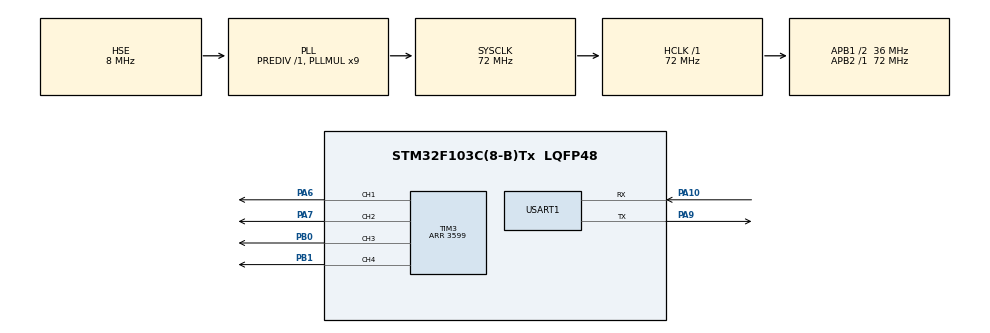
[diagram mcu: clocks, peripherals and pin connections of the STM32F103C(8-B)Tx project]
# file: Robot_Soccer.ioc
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FREERTOS.Tasks01=defaultTask,24,128,StartDefaultTask,Default,NULL,Dynamic,NULL,NULL;UART_Task,32,128,StartUARTTask,Default,NULL,Dynamic,NULL,NULL;Motor_Task,24,128,StartMotorTask,Default,NULL,Dynamic,NULL,NULL
Mcu.Family=STM32F1
Mcu.Name=STM32F103C(8-B)Tx
Mcu.Package=LQFP48
NVIC.PriorityGroup=NVIC_PRIORITYGROUP_4
NVIC.TIM2_IRQn=true\:15\:0\:false\:false\:true\:false\:false\:true\:true
NVIC.TimeBase=TIM2_IRQn
NVIC.TimeBaseIP=TIM2
NVIC.USART1_IRQn=true\:5\:0\:false\:false\:true\:true\:true\:true\:true
PA10.Mode=Asynchronous
PA10.Signal=USART1_RX
PA13.Mode=Serial_Wire
PA13.Signal=SYS_JTMS-SWDIO
PA14.Mode=Serial_Wire
PA14.Signal=SYS_JTCK-SWCLK
PA6.Signal=S_TIM3_CH1
PA7.Signal=S_TIM3_CH2
PA9.Mode=Asynchronous
PA9.Signal=USART1_TX
PB0.Signal=S_TIM3_CH3
PB1.Signal=S_TIM3_CH4
PD0-OSC_IN.Mode=HSE-External-Oscillator
PD0-OSC_IN.Signal=RCC_OSC_IN
PD1-OSC_OUT.Mode=HSE-External-Oscillator
PD1-OSC_OUT.Signal=RCC_OSC_OUT
ProjectManager.HeapSize=0x200
ProjectManager.StackSize=0x400
ProjectManager.TargetToolchain=Makefile
RCC.AHBFreq_Value=72000000
RCC.APB1CLKDivider=RCC_HCLK_DIV2
RCC.APB1Freq_Value=36000000
RCC.APB1TimFreq_Value=72000000
RCC.APB2Freq_Value=72000000
RCC.APB2TimFreq_Value=72000000
RCC.HCLKFreq_Value=72000000
RCC.PLLMUL=RCC_PLL_MUL9
RCC.PLLSourceVirtual=RCC_PLLSOURCE_HSE
RCC.SYSCLKFreq_VALUE=72000000
RCC.SYSCLKSource=RCC_SYSCLKSOURCE_PLLCLK
RCC.USBFreq_Value=72000000
SH.S_TIM3_CH1.0=TIM3_CH1,PWM Generation1 CH1
SH.S_TIM3_CH2.0=TIM3_CH2,PWM Generation2 CH2
SH.S_TIM3_CH3.0=TIM3_CH3,PWM Generation3 CH3
SH.S_TIM3_CH4.0=TIM3_CH4,PWM Generation4 CH4
TIM3.Channel-PWM\ Generation1\ CH1=TIM_CHANNEL_1
TIM3.Channel-PWM\ Generation2\ CH2=TIM_CHANNEL_2
TIM3.Channel-PWM\ Generation3\ CH3=TIM_CHANNEL_3
TIM3.Channel-PWM\ Generation4\ CH4=TIM_CHANNEL_4
TIM3.Period=3599
USART1.VirtualMode=VM_ASYNC
VP_FREERTOS_VS_CMSIS_V2.Mode=CMSIS_V2
VP_SYS_VS_tim2.Mode=TIM2
VP_TIM3_VS_ClockSourceINT.Mode=Internal
board=custom

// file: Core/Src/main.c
/* USER CODE BEGIN Header */
/**
  ******************************************************************************
  * @file           : main.c
  * @brief          : Main program body
  ******************************************************************************
  * @attention
  *
  * Copyright (c) 2026 STMicroelectronics.
  * All rights reserved.
  *
  * This software is licensed under terms that can be found in the LICENSE file
  * in the root directory of this software component.
  * If no LICENSE file comes with this software, it is provided AS-IS.
  *
  ******************************************************************************
  */
/* USER CODE END Header */
#include "main.h"
#include "cmsis_os.h"
#include "tim.h"
#include "usart.h"
#include "gpio.h"

/* USER CODE BEGIN Includes */
#include "motor.h"
#include "bluetooth.h"

/* USER CODE END Includes */

void SystemClock_Config(void);
void MX_FREERTOS_Init(void);

int main(void)
{

  /* MCU Configuration--------------------------------------------------------*/

  /* Reset of all peripherals, Initializes the Flash interface and the Systick. */
  HAL_Init();

  /* Configure the system clock */
  SystemClock_Config();

  /* Initialize all configured peripherals */
  MX_GPIO_Init();
  MX_TIM3_Init();
  MX_USART1_UART_Init();
  /* USER CODE BEGIN 2 */

  /* Initialize Motor Control */
  Motor_Init();

  /* Initialize Bluetooth Communication */
  Bluetooth_Init();

  /* USER CODE END 2 */

  /* Init scheduler */
  osKernelInitialize();  /* Call init function for freertos objects (in cmsis_os2.c) */
  MX_FREERTOS_Init();

  /* Start scheduler */
  osKernelStart();

  /* We should never get here as control is now taken by the scheduler */

  /* Infinite loop */
  while (1)
  {

  }
}

void SystemClock_Config(void)
{
  RCC_OscInitTypeDef RCC_OscInitStruct = {0};
  RCC_ClkInitTypeDef RCC_ClkInitStruct = {0};

  /** Initializes the RCC Oscillators according to the specified parameters
  * in the RCC_OscInitTypeDef structure.
  */
  RCC_OscInitStruct.OscillatorType = RCC_OSCILLATORTYPE_HSE;
  RCC_OscInitStruct.HSEState = RCC_HSE_ON;
  RCC_OscInitStruct.HSEPredivValue = RCC_HSE_PREDIV_DIV1;
  RCC_OscInitStruct.HSIState = RCC_HSI_ON;
  RCC_OscInitStruct.PLL.PLLState = RCC_PLL_ON;
  RCC_OscInitStruct.PLL.PLLSource = RCC_PLLSOURCE_HSE;
  RCC_OscInitStruct.PLL.PLLMUL = RCC_PLL_MUL9;
  if (HAL_RCC_OscConfig(&RCC_OscInitStruct) != HAL_OK)
  {
    Error_Handler();
  }

  /** Initializes the CPU, AHB and APB buses clocks
  */
  RCC_ClkInitStruct.ClockType = RCC_CLOCKTYPE_HCLK|RCC_CLOCKTYPE_SYSCLK
                              |RCC_CLOCKTYPE_PCLK1|RCC_CLOCKTYPE_PCLK2;
  RCC_ClkInitStruct.SYSCLKSource = RCC_SYSCLKSOURCE_PLLCLK;
  RCC_ClkInitStruct.AHBCLKDivider = RCC_SYSCLK_DIV1;
  RCC_ClkInitStruct.APB1CLKDivider = RCC_HCLK_DIV2;
  RCC_ClkInitStruct.APB2CLKDivider = RCC_HCLK_DIV1;

  if (HAL_RCC_ClockConfig(&RCC_ClkInitStruct, FLASH_LATENCY_2) != HAL_OK)
  {
    Error_Handler();
  }
}

void HAL_TIM_PeriodElapsedCallback(TIM_HandleTypeDef *htim)
{
  if (htim->Instance == TIM2)
  {
    HAL_IncTick();
  }
}

void Error_Handler(void)
{
  __disable_irq();
  while (1)
  {
  }
}

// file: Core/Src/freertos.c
/* USER CODE BEGIN Header */
/**
  ******************************************************************************
  * File Name          : freertos.c
  * Description        : Code for freertos applications
  ******************************************************************************
  * @attention
  *
  * Copyright (c) 2026 STMicroelectronics.
  * All rights reserved.
  *
  * This software is licensed under terms that can be found in the LICENSE file
  * in the root directory of this software component.
  * If no LICENSE file comes with this software, it is provided AS-IS.
  *
  ******************************************************************************
  */
/* USER CODE END Header */

#include "FreeRTOS.h"
#include "task.h"
#include "main.h"
#include "cmsis_os.h"

/* USER CODE BEGIN Includes */
#include "motor.h"
#include "bluetooth.h"
#include "main.h"

/* USER CODE END Includes */

/* Definitions for defaultTask */
osThreadId_t defaultTaskHandle;
const osThreadAttr_t defaultTask_attributes = {
  .name = "defaultTask",
  .stack_size = 128 * 4,
  .priority = (osPriority_t) osPriorityNormal,
};
/* Definitions for UART_Task */
osThreadId_t UART_TaskHandle;
const osThreadAttr_t UART_Task_attributes = {
  .name = "UART_Task",
  .stack_size = 128 * 4,
  .priority = (osPriority_t) osPriorityAboveNormal,
};
/* Definitions for Motor_Task */
osThreadId_t Motor_TaskHandle;
const osThreadAttr_t Motor_Task_attributes = {
  .name = "Motor_Task",
  .stack_size = 128 * 4,
  .priority = (osPriority_t) osPriorityNormal,
};

void StartDefaultTask(void *argument);
void StartUARTTask(void *argument);
void StartMotorTask(void *argument);

void MX_FREERTOS_Init(void); /* (MISRA C 2004 rule 8.1) */

void MX_FREERTOS_Init(void) {

  /* Create the thread(s) */
  /* creation of defaultTask */
  defaultTaskHandle = osThreadNew(StartDefaultTask, NULL, &defaultTask_attributes);

  /* creation of UART_Task */
  UART_TaskHandle = osThreadNew(StartUARTTask, NULL, &UART_Task_attributes);

  /* creation of Motor_Task */
  Motor_TaskHandle = osThreadNew(StartMotorTask, NULL, &Motor_Task_attributes);

}

void StartDefaultTask(void *argument)
{
  /* USER CODE BEGIN StartDefaultTask */
  /* Infinite loop */
  for(;;)
  {
    /* Heartbeat LED on PC13 - blink every 500ms */
    HAL_GPIO_TogglePin(GPIOC, GPIO_PIN_13);
    osDelay(500);
  }
  /* USER CODE END StartDefaultTask */
}

void StartUARTTask(void *argument)
{
  /* USER CODE BEGIN StartUARTTask */
  /* Infinite loop */
  for(;;)
  {
    /* Bluetooth processing is done in interrupt callback */
    /* This task can be used for additional UART processing if needed */
    osDelay(10);
  }
  /* USER CODE END StartUARTTask */
}

void StartMotorTask(void *argument)
{
  /* USER CODE BEGIN StartMotorTask */
  /* Infinite loop */
  for(;;)
  {
    /* Check for auto-stop timeout - stop motors if no command for 1 second */
    Motor_CheckTimeout();

    /* Check every 100ms for timeout */
    osDelay(100);
  }
  /* USER CODE END StartMotorTask */
}
